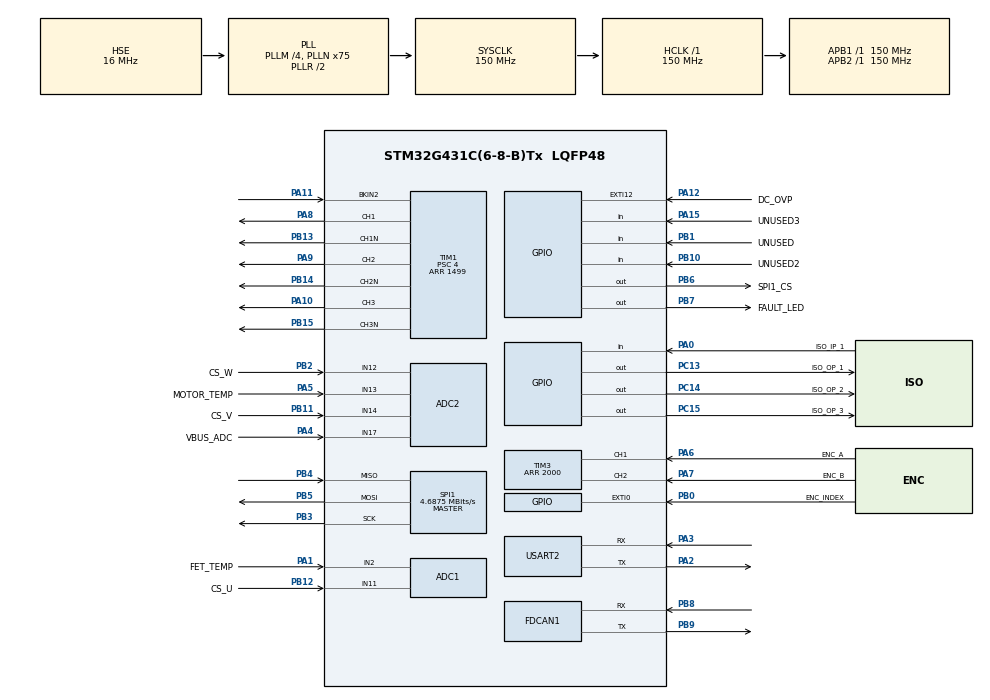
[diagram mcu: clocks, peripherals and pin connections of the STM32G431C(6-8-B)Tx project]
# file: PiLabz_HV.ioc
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ADC1.DMAContinuousRequests=ENABLE
ADC1.EnableRegularConversion=DISABLE
ADC1.GainCompensation=0
ADC1.OversamplingMode=ENABLE
ADC1.master=1
ADC2.DMAContinuousRequests=DISABLE
ADC2.EnableRegularConversion=DISABLE
ADC2.OversamplingMode=ENABLE
Dma.ADC1.0.Direction=DMA_PERIPH_TO_MEMORY
Dma.ADC1.0.EventEnable=DISABLE
Dma.ADC1.0.Instance=DMA1_Channel1
Dma.ADC1.0.MemDataAlignment=DMA_MDATAALIGN_HALFWORD
Dma.ADC1.0.MemInc=DMA_MINC_ENABLE
Dma.ADC1.0.Mode=DMA_CIRCULAR
Dma.ADC1.0.PeriphDataAlignment=DMA_PDATAALIGN_HALFWORD
Dma.ADC1.0.PeriphInc=DMA_PINC_DISABLE
Dma.ADC1.0.Polarity=HAL_DMAMUX_REQ_GEN_RISING
Dma.ADC1.0.Priority=DMA_PRIORITY_LOW
Dma.ADC1.0.RequestNumber=1
Dma.ADC1.0.SignalID=NONE
Dma.ADC1.0.SyncEnable=DISABLE
Dma.ADC1.0.SyncPolarity=HAL_DMAMUX_SYNC_NO_EVENT
Dma.ADC1.0.SyncRequestNumber=1
Dma.ADC1.0.SyncSignalID=NONE
Dma.Request0=ADC1
FDCAN1.CalculateBaudRateNominal=1874999
FDCAN1.CalculateTimeBitNominal=533
FDCAN1.CalculateTimeQuantumNominal=106.66666666666667
Mcu.Family=STM32G4
Mcu.Name=STM32G431C(6-8-B)Tx
Mcu.Package=LQFP48
NVIC.ADC1_2_IRQn=true\:0\:0\:false\:false\:true\:true\:true\:true
NVIC.DMA1_Channel1_IRQn=true\:0\:0\:false\:false\:true\:false\:true\:true
NVIC.PriorityGroup=NVIC_PRIORITYGROUP_4
NVIC.SPI1_IRQn=true\:0\:0\:false\:false\:true\:true\:true\:true
NVIC.TIM1_BRK_TIM15_IRQn=true\:0\:0\:true\:false\:true\:true\:true\:true
NVIC.TIM1_TRG_COM_TIM17_IRQn=true\:0\:0\:false\:false\:true\:true\:true\:true
NVIC.TIM1_UP_TIM16_IRQn=true\:1\:0\:true\:false\:true\:true\:true\:true
PA0.GPIO_Label=ISO_IP_1
PA0.Signal=GPIO_Input
PA1.GPIO_Label=FET_TEMP
PA1.Mode=IN2-Single-Ended
PA1.Signal=ADC1_IN2
PA10.Signal=S_TIM1_CH3
PA11.Mode=Activate-Break-Input-2
PA11.Signal=TIM1_BKIN2
PA12.GPIO_Label=DC_OVP
PA12.Signal=GPXTI12
PA13.Mode=Serial_Wire
PA13.Signal=SYS_JTMS-SWDIO
PA14.Mode=Serial_Wire
PA14.Signal=SYS_JTCK-SWCLK
PA15.GPIO_Label=UNUSED3
PA15.GPIO_PuPd=GPIO_PULLUP
PA15.Signal=GPIO_Input
PA2.Mode=Asynchronous
PA2.Signal=USART2_TX
PA3.Mode=Asynchronous
PA3.Signal=USART2_RX
PA4.GPIO_Label=VBUS_ADC
PA4.Mode=IN17-Single-Ended
PA4.Signal=ADC2_IN17
PA5.GPIO_Label=MOTOR_TEMP
PA5.Mode=IN13-Single-Ended
PA5.Signal=ADC2_IN13
PA6.GPIO_Label=ENC_A
PA6.Signal=S_TIM3_CH1
PA7.GPIO_Label=ENC_B
PA7.Signal=S_TIM3_CH2
PA8.Signal=S_TIM1_CH1
PA9.Signal=S_TIM1_CH2
PB0.GPIO_Label=ENC_INDEX
PB0.Signal=GPXTI0
PB1.GPIO_Label=UNUSED
PB1.GPIO_PuPd=GPIO_PULLUP
PB1.Signal=GPIO_Input
PB10.GPIO_Label=UNUSED2
PB10.GPIO_PuPd=GPIO_PULLUP
PB10.Signal=GPIO_Input
PB11.GPIO_Label=CS_V
PB11.Mode=IN14-Single-Ended
PB11.Signal=ADC2_IN14
PB12.GPIO_Label=CS_U
PB12.Mode=IN11-Single-Ended
PB12.Signal=ADC1_IN11
PB13.Mode=PWM Generation1 CH1 CH1N
PB13.Signal=TIM1_CH1N
PB14.Mode=PWM Generation2 CH2 CH2N
PB14.Signal=TIM1_CH2N
PB15.Mode=PWM Generation3 CH3 CH3N
PB15.Signal=TIM1_CH3N
PB2.GPIO_Label=CS_W
PB2.Mode=IN12-Single-Ended
PB2.Signal=ADC2_IN12
PB3.Mode=Full_Duplex_Master
PB3.Signal=SPI1_SCK
PB4.Mode=Full_Duplex_Master
PB4.Signal=SPI1_MISO
PB5.Mode=Full_Duplex_Master
PB5.Signal=SPI1_MOSI
PB6.GPIO_Label=SPI1_CS
PB6.GPIO_ModeDefaultOutputPP=GPIO_MODE_OUTPUT_PP
PB6.GPIO_PuPd=GPIO_NOPULL
PB6.PinState=GPIO_PIN_RESET
PB6.Signal=GPIO_Output
PB7.GPIO_Label=FAULT_LED
PB7.GPIO_ModeDefaultOutputPP=GPIO_MODE_OUTPUT_OD
PB7.GPIO_PuPd=GPIO_NOPULL
PB7.Signal=GPIO_Output
PB8-BOOT0.Mode=FDCAN_Activate
PB8-BOOT0.Signal=FDCAN1_RX
PB9.Mode=FDCAN_Activate
PB9.Signal=FDCAN1_TX
PC13.GPIO_Label=ISO_OP_1
PC13.GPIO_ModeDefaultOutputPP=GPIO_MODE_OUTPUT_OD
PC13.GPIO_PuPd=GPIO_NOPULL
PC13.Signal=GPIO_Output
PC14-OSC32_IN.GPIO_Label=ISO_OP_2
PC14-OSC32_IN.GPIO_ModeDefaultOutputPP=GPIO_MODE_OUTPUT_OD
PC14-OSC32_IN.GPIO_PuPd=GPIO_NOPULL
PC14-OSC32_IN.Signal=GPIO_Output
PC15-OSC32_OUT.GPIO_Label=ISO_OP_3
PC15-OSC32_OUT.GPIO_ModeDefaultOutputPP=GPIO_MODE_OUTPUT_OD
PC15-OSC32_OUT.GPIO_PuPd=GPIO_NOPULL
PC15-OSC32_OUT.PinState=GPIO_PIN_RESET
PC15-OSC32_OUT.Signal=GPIO_Output
PF0-OSC_IN.Mode=HSE-External-Oscillator
PF0-OSC_IN.Signal=RCC_OSC_IN
PF1-OSC_OUT.Mode=HSE-External-Oscillator
PF1-OSC_OUT.Signal=RCC_OSC_OUT
ProjectManager.HeapSize=0x200
ProjectManager.StackSize=0x400
ProjectManager.TargetToolchain=STM32CubeIDE
RCC.ADC12Freq_Value=150000000
RCC.AHBFreq_Value=150000000
RCC.APB1Freq_Value=150000000
RCC.APB1TimFreq_Value=150000000
RCC.APB2Freq_Value=150000000
RCC.APB2TimFreq_Value=150000000
RCC.CortexFreq_Value=150000000
RCC.EXTERNAL_CLOCK_VALUE=12288000
RCC.HCLKFreq_Value=150000000
RCC.HSE_VALUE=16000000
RCC.HSI48_VALUE=48000000
RCC.HSI_VALUE=16000000
RCC.LSE_VALUE=32768
RCC.PLLM=RCC_PLLM_DIV4
RCC.PLLN=75
RCC.PLLSourceVirtual=RCC_PLLSOURCE_HSE
RCC.SYSCLKFreq_VALUE=150000000
RCC.SYSCLKSource=RCC_SYSCLKSOURCE_PLLCLK
RCC.USBFreq_Value=150000000
RCC.VCOOutputFreq_Value=300000000
SH.S_TIM1_CH1.0=TIM1_CH1,PWM Generation1 CH1 CH1N
SH.S_TIM1_CH2.0=TIM1_CH2,PWM Generation2 CH2 CH2N
SH.S_TIM1_CH3.0=TIM1_CH3,PWM Generation3 CH3 CH3N
SH.S_TIM3_CH1.0=TIM3_CH1,Encoder_Interface
SH.S_TIM3_CH2.0=TIM3_CH2,Encoder_Interface
SPI1.BaudRatePrescaler=SPI_BAUDRATEPRESCALER_32
SPI1.CLKPhase=SPI_PHASE_2EDGE
SPI1.CalculateBaudRate=4.6875 MBits/s
SPI1.DataSize=SPI_DATASIZE_8BIT
SPI1.Direction=SPI_DIRECTION_2LINES
SPI1.Mode=SPI_MODE_MASTER
SPI1.VirtualType=VM_MASTER
TIM1.Channel-PWM\ Generation1\ CH1\ CH1N=TIM_CHANNEL_1
TIM1.Channel-PWM\ Generation2\ CH2\ CH2N=TIM_CHANNEL_2
TIM1.Channel-PWM\ Generation3\ CH3\ CH3N=TIM_CHANNEL_3
TIM1.CounterMode=TIM_COUNTERMODE_UP
TIM1.DeadTime=90
TIM1.DeadTimePreload=ENABLE
TIM1.OCMode_PWM-PWM\ Generation1\ CH1\ CH1N=TIM_OCMODE_PWM1
TIM1.OCNIdleState_1=TIM_OCNIDLESTATE_SET
TIM1.OCNIdleState_2=TIM_OCNIDLESTATE_SET
TIM1.OCNIdleState_3=TIM_OCNIDLESTATE_SET
TIM1.OCNPolarity_1=TIM_OCNPOLARITY_LOW
TIM1.OCNPolarity_2=TIM_OCNPOLARITY_LOW
TIM1.OCNPolarity_3=TIM_OCNPOLARITY_LOW
TIM1.PeriodNoDither=1499
TIM1.Prescaler=4
TIM3.PeriodNoDither=2000
USART2.VirtualMode-Asynchronous=VM_ASYNC
VP_SYS_VS_DBSignals.Mode=DisableDeadBatterySignals
VP_TIM1_VS_ClockSourceINT.Mode=Internal
board=custom

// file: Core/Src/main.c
/* USER CODE BEGIN Header */
/**
  ******************************************************************************
  * @file           : main.c
  * @brief          : Main program body
  ******************************************************************************
  * @attention
  *
  * Copyright (c) 2024 STMicroelectronics.
  * All rights reserved.
  *
  * This software is licensed under terms that can be found in the LICENSE file
  * in the root directory of this software component.
  * If no LICENSE file comes with this software, it is provided AS-IS.
  *
  ******************************************************************************
  */
/* USER CODE END Header */
#include "main.h"

/* USER CODE BEGIN Includes */
#include "EncoderFns.h"
/* USER CODE END Includes */

ADC_HandleTypeDef hadc1;
ADC_HandleTypeDef hadc2;
DMA_HandleTypeDef hdma_adc1;

FDCAN_HandleTypeDef hfdcan1;

SPI_HandleTypeDef hspi1;

TIM_HandleTypeDef htim1;
TIM_HandleTypeDef htim3;

UART_HandleTypeDef huart2;

void SystemClock_Config(void);
static void MX_GPIO_Init(void);
static void MX_DMA_Init(void);
static void MX_ADC1_Init(void);
static void MX_ADC2_Init(void);
static void MX_FDCAN1_Init(void);
static void MX_SPI1_Init(void);
static void MX_TIM1_Init(void);
static void MX_TIM3_Init(void);
static void MX_USART2_UART_Init(void);

/* USER CODE BEGIN 0 */
float angleMech=0;
/* USER CODE END 0 */

int main(void)
{

  /* MCU Configuration--------------------------------------------------------*/

  /* Reset of all peripherals, Initializes the Flash interface and the Systick. */
  HAL_Init();

  /* Configure the system clock */
  SystemClock_Config();

  /* Initialize all configured peripherals */
  MX_GPIO_Init();
  MX_DMA_Init();
  MX_ADC1_Init();
  MX_ADC2_Init();
  MX_FDCAN1_Init();
  MX_SPI1_Init();
  MX_TIM1_Init();
  MX_TIM3_Init();
  MX_USART2_UART_Init();

  /* Infinite loop */
  /* USER CODE BEGIN WHILE */
  while (1)
  {

	angleMech = getEncoderAngleFromSPI(1);
	HAL_GPIO_TogglePin(GPIOB,FAULT_LED_Pin);
	HAL_Delay(100);

    /* USER CODE END WHILE */

  }
}

void SystemClock_Config(void)
{
  RCC_OscInitTypeDef RCC_OscInitStruct = {0};
  RCC_ClkInitTypeDef RCC_ClkInitStruct = {0};

  /** Configure the main internal regulator output voltage
  */
  HAL_PWREx_ControlVoltageScaling(PWR_REGULATOR_VOLTAGE_SCALE1);

  /** Initializes the RCC Oscillators according to the specified parameters
  * in the RCC_OscInitTypeDef structure.
  */
  RCC_OscInitStruct.OscillatorType = RCC_OSCILLATORTYPE_HSE;
  RCC_OscInitStruct.HSEState = RCC_HSE_ON;
  RCC_OscInitStruct.PLL.PLLState = RCC_PLL_ON;
  RCC_OscInitStruct.PLL.PLLSource = RCC_PLLSOURCE_HSE;
  RCC_OscInitStruct.PLL.PLLM = RCC_PLLM_DIV4;
  RCC_OscInitStruct.PLL.PLLN = 75;
  RCC_OscInitStruct.PLL.PLLP = RCC_PLLP_DIV2;
  RCC_OscInitStruct.PLL.PLLQ = RCC_PLLQ_DIV2;
  RCC_OscInitStruct.PLL.PLLR = RCC_PLLR_DIV2;
  if (HAL_RCC_OscConfig(&RCC_OscInitStruct) != HAL_OK)
  {
    Error_Handler();
  }

  /** Initializes the CPU, AHB and APB buses clocks
  */
  RCC_ClkInitStruct.ClockType = RCC_CLOCKTYPE_HCLK|RCC_CLOCKTYPE_SYSCLK
                              |RCC_CLOCKTYPE_PCLK1|RCC_CLOCKTYPE_PCLK2;
  RCC_ClkInitStruct.SYSCLKSource = RCC_SYSCLKSOURCE_PLLCLK;
  RCC_ClkInitStruct.AHBCLKDivider = RCC_SYSCLK_DIV1;
  RCC_ClkInitStruct.APB1CLKDivider = RCC_HCLK_DIV1;
  RCC_ClkInitStruct.APB2CLKDivider = RCC_HCLK_DIV1;

  if (HAL_RCC_ClockConfig(&RCC_ClkInitStruct, FLASH_LATENCY_4) != HAL_OK)
  {
    Error_Handler();
  }
}

static void MX_ADC1_Init(void)
{

  ADC_MultiModeTypeDef multimode = {0};

  /** Common config
  */
  hadc1.Instance = ADC1;
  hadc1.Init.ClockPrescaler = ADC_CLOCK_SYNC_PCLK_DIV4;
  hadc1.Init.Resolution = ADC_RESOLUTION_12B;
  hadc1.Init.DataAlign = ADC_DATAALIGN_RIGHT;
  hadc1.Init.GainCompensation = 0;
  hadc1.Init.ScanConvMode = ADC_SCAN_DISABLE;
  hadc1.Init.EOCSelection = ADC_EOC_SINGLE_CONV;
  hadc1.Init.LowPowerAutoWait = DISABLE;
  hadc1.Init.ContinuousConvMode = DISABLE;
  hadc1.Init.NbrOfConversion = 1;
  hadc1.Init.DiscontinuousConvMode = DISABLE;
  hadc1.Init.DMAContinuousRequests = ENABLE;
  hadc1.Init.Overrun = ADC_OVR_DATA_PRESERVED;
  hadc1.Init.OversamplingMode = ENABLE;
  if (HAL_ADC_Init(&hadc1) != HAL_OK)
  {
    Error_Handler();
  }

  /** Configure the ADC multi-mode
  */
  multimode.Mode = ADC_MODE_INDEPENDENT;
  if (HAL_ADCEx_MultiModeConfigChannel(&hadc1, &multimode) != HAL_OK)
  {
    Error_Handler();
  }

}

static void MX_ADC2_Init(void)
{

  /** Common config
  */
  hadc2.Instance = ADC2;
  hadc2.Init.ClockPrescaler = ADC_CLOCK_SYNC_PCLK_DIV4;
  hadc2.Init.Resolution = ADC_RESOLUTION_12B;
  hadc2.Init.DataAlign = ADC_DATAALIGN_RIGHT;
  hadc2.Init.GainCompensation = 0;
  hadc2.Init.ScanConvMode = ADC_SCAN_DISABLE;
  hadc2.Init.EOCSelection = ADC_EOC_SINGLE_CONV;
  hadc2.Init.LowPowerAutoWait = DISABLE;
  hadc2.Init.ContinuousConvMode = DISABLE;
  hadc2.Init.NbrOfConversion = 1;
  hadc2.Init.DiscontinuousConvMode = DISABLE;
  hadc2.Init.DMAContinuousRequests = DISABLE;
  hadc2.Init.Overrun = ADC_OVR_DATA_PRESERVED;
  hadc2.Init.OversamplingMode = ENABLE;
  if (HAL_ADC_Init(&hadc2) != HAL_OK)
  {
    Error_Handler();
  }

}

static void MX_FDCAN1_Init(void)
{

  hfdcan1.Instance = FDCAN1;
  hfdcan1.Init.ClockDivider = FDCAN_CLOCK_DIV1;
  hfdcan1.Init.FrameFormat = FDCAN_FRAME_CLASSIC;
  hfdcan1.Init.Mode = FDCAN_MODE_NORMAL;
  hfdcan1.Init.AutoRetransmission = DISABLE;
  hfdcan1.Init.TransmitPause = DISABLE;
  hfdcan1.Init.ProtocolException = DISABLE;
  hfdcan1.Init.NominalPrescaler = 16;
  hfdcan1.Init.NominalSyncJumpWidth = 1;
  hfdcan1.Init.NominalTimeSeg1 = 2;
  hfdcan1.Init.NominalTimeSeg2 = 2;
  hfdcan1.Init.DataPrescaler = 1;
  hfdcan1.Init.DataSyncJumpWidth = 1;
  hfdcan1.Init.DataTimeSeg1 = 1;
  hfdcan1.Init.DataTimeSeg2 = 1;
  hfdcan1.Init.StdFiltersNbr = 0;
  hfdcan1.Init.ExtFiltersNbr = 0;
  hfdcan1.Init.TxFifoQueueMode = FDCAN_TX_FIFO_OPERATION;
  if (HAL_FDCAN_Init(&hfdcan1) != HAL_OK)
  {
    Error_Handler();
  }

}

static void MX_SPI1_Init(void)
{

  /* SPI1 parameter configuration*/
  hspi1.Instance = SPI1;
  hspi1.Init.Mode = SPI_MODE_MASTER;
  hspi1.Init.Direction = SPI_DIRECTION_2LINES;
  hspi1.Init.DataSize = SPI_DATASIZE_8BIT;
  hspi1.Init.CLKPolarity = SPI_POLARITY_LOW;
  hspi1.Init.CLKPhase = SPI_PHASE_2EDGE;
  hspi1.Init.NSS = SPI_NSS_SOFT;
  hspi1.Init.BaudRatePrescaler = SPI_BAUDRATEPRESCALER_32;
  hspi1.Init.FirstBit = SPI_FIRSTBIT_MSB;
  hspi1.Init.TIMode = SPI_TIMODE_DISABLE;
  hspi1.Init.CRCCalculation = SPI_CRCCALCULATION_DISABLE;
  hspi1.Init.CRCPolynomial = 7;
  hspi1.Init.CRCLength = SPI_CRC_LENGTH_DATASIZE;
  hspi1.Init.NSSPMode = SPI_NSS_PULSE_DISABLE;
  if (HAL_SPI_Init(&hspi1) != HAL_OK)
  {
    Error_Handler();
  }

}

static void MX_TIM1_Init(void)
{

  TIM_ClockConfigTypeDef sClockSourceConfig = {0};
  TIM_MasterConfigTypeDef sMasterConfig = {0};
  TIMEx_BreakInputConfigTypeDef sBreakInputConfig = {0};
  TIM_OC_InitTypeDef sConfigOC = {0};
  TIM_BreakDeadTimeConfigTypeDef sBreakDeadTimeConfig = {0};

  htim1.Instance = TIM1;
  htim1.Init.Prescaler = 4;
  htim1.Init.CounterMode = TIM_COUNTERMODE_UP;
  htim1.Init.Period = 1499;
  htim1.Init.ClockDivision = TIM_CLOCKDIVISION_DIV1;
  htim1.Init.RepetitionCounter = 0;
  htim1.Init.AutoReloadPreload = TIM_AUTORELOAD_PRELOAD_DISABLE;
  if (HAL_TIM_Base_Init(&htim1) != HAL_OK)
  {
    Error_Handler();
  }
  sClockSourceConfig.ClockSource = TIM_CLOCKSOURCE_INTERNAL;
  if (HAL_TIM_ConfigClockSource(&htim1, &sClockSourceConfig) != HAL_OK)
  {
    Error_Handler();
  }
  if (HAL_TIM_PWM_Init(&htim1) != HAL_OK)
  {
    Error_Handler();
  }
  sMasterConfig.MasterOutputTrigger = TIM_TRGO_RESET;
  sMasterConfig.MasterOutputTrigger2 = TIM_TRGO2_RESET;
  sMasterConfig.MasterSlaveMode = TIM_MASTERSLAVEMODE_DISABLE;
  if (HAL_TIMEx_MasterConfigSynchronization(&htim1, &sMasterConfig) != HAL_OK)
  {
    Error_Handler();
  }
  sBreakInputConfig.Source = TIM_BREAKINPUTSOURCE_BKIN;
  sBreakInputConfig.Enable = TIM_BREAKINPUTSOURCE_ENABLE;
  sBreakInputConfig.Polarity = TIM_BREAKINPUTSOURCE_POLARITY_HIGH;
  if (HAL_TIMEx_ConfigBreakInput(&htim1, TIM_BREAKINPUT_BRK2, &sBreakInputConfig) != HAL_OK)
  {
    Error_Handler();
  }
  sConfigOC.OCMode = TIM_OCMODE_PWM1;
  sConfigOC.Pulse = 0;
  sConfigOC.OCPolarity = TIM_OCPOLARITY_HIGH;
  sConfigOC.OCNPolarity = TIM_OCNPOLARITY_LOW;
  sConfigOC.OCFastMode = TIM_OCFAST_DISABLE;
  sConfigOC.OCIdleState = TIM_OCIDLESTATE_RESET;
  sConfigOC.OCNIdleState = TIM_OCNIDLESTATE_SET;
  if (HAL_TIM_PWM_ConfigChannel(&htim1, &sConfigOC, TIM_CHANNEL_1) != HAL_OK)
  {
    Error_Handler();
  }
  if (HAL_TIM_PWM_ConfigChannel(&htim1, &sConfigOC, TIM_CHANNEL_2) != HAL_OK)
  {
    Error_Handler();
  }
  if (HAL_TIM_PWM_ConfigChannel(&htim1, &sConfigOC, TIM_CHANNEL_3) != HAL_OK)
  {
    Error_Handler();
  }
  HAL_TIMEx_EnableDeadTimePreload(&htim1);
  sBreakDeadTimeConfig.OffStateRunMode = TIM_OSSR_ENABLE;
  sBreakDeadTimeConfig.OffStateIDLEMode = TIM_OSSI_ENABLE;
  sBreakDeadTimeConfig.LockLevel = TIM_LOCKLEVEL_OFF;
  sBreakDeadTimeConfig.DeadTime = 90;
  sBreakDeadTimeConfig.BreakState = TIM_BREAK_DISABLE;
  sBreakDeadTimeConfig.BreakPolarity = TIM_BREAKPOLARITY_HIGH;
  sBreakDeadTimeConfig.BreakFilter = 0;
  sBreakDeadTimeConfig.BreakAFMode = TIM_BREAK_AFMODE_INPUT;
  sBreakDeadTimeConfig.Break2State = TIM_BREAK2_ENABLE;
  sBreakDeadTimeConfig.Break2Polarity = TIM_BREAK2POLARITY_HIGH;
  sBreakDeadTimeConfig.Break2Filter = 0;
  sBreakDeadTimeConfig.Break2AFMode = TIM_BREAK_AFMODE_INPUT;
  sBreakDeadTimeConfig.AutomaticOutput = TIM_AUTOMATICOUTPUT_DISABLE;
  if (HAL_TIMEx_ConfigBreakDeadTime(&htim1, &sBreakDeadTimeConfig) != HAL_OK)
  {
    Error_Handler();
  }
  HAL_TIM_MspPostInit(&htim1);

}

static void MX_TIM3_Init(void)
{

  TIM_Encoder_InitTypeDef sConfig = {0};
  TIM_MasterConfigTypeDef sMasterConfig = {0};

  htim3.Instance = TIM3;
  htim3.Init.Prescaler = 0;
  htim3.Init.CounterMode = TIM_COUNTERMODE_UP;
  htim3.Init.Period = 2000;
  htim3.Init.ClockDivision = TIM_CLOCKDIVISION_DIV1;
  htim3.Init.AutoReloadPreload = TIM_AUTORELOAD_PRELOAD_DISABLE;
  sConfig.EncoderMode = TIM_ENCODERMODE_TI1;
  sConfig.IC1Polarity = TIM_ICPOLARITY_RISING;
  sConfig.IC1Selection = TIM_ICSELECTION_DIRECTTI;
  sConfig.IC1Prescaler = TIM_ICPSC_DIV1;
  sConfig.IC1Filter = 0;
  sConfig.IC2Polarity = TIM_ICPOLARITY_RISING;
  sConfig.IC2Selection = TIM_ICSELECTION_DIRECTTI;
  sConfig.IC2Prescaler = TIM_ICPSC_DIV1;
  sConfig.IC2Filter = 0;
  if (HAL_TIM_Encoder_Init(&htim3, &sConfig) != HAL_OK)
  {
    Error_Handler();
  }
  sMasterConfig.MasterOutputTrigger = TIM_TRGO_RESET;
  sMasterConfig.MasterSlaveMode = TIM_MASTERSLAVEMODE_DISABLE;
  if (HAL_TIMEx_MasterConfigSynchronization(&htim3, &sMasterConfig) != HAL_OK)
  {
    Error_Handler();
  }

}

static void MX_USART2_UART_Init(void)
{

  huart2.Instance = USART2;
  huart2.Init.BaudRate = 115200;
  huart2.Init.WordLength = UART_WORDLENGTH_8B;
  huart2.Init.StopBits = UART_STOPBITS_1;
  huart2.Init.Parity = UART_PARITY_NONE;
  huart2.Init.Mode = UART_MODE_TX_RX;
  huart2.Init.HwFlowCtl = UART_HWCONTROL_NONE;
  huart2.Init.OverSampling = UART_OVERSAMPLING_16;
  huart2.Init.OneBitSampling = UART_ONE_BIT_SAMPLE_DISABLE;
  huart2.Init.ClockPrescaler = UART_PRESCALER_DIV1;
  huart2.AdvancedInit.AdvFeatureInit = UART_ADVFEATURE_NO_INIT;
  if (HAL_UART_Init(&huart2) != HAL_OK)
  {
    Error_Handler();
  }
  if (HAL_UARTEx_SetTxFifoThreshold(&huart2, UART_TXFIFO_THRESHOLD_1_8) != HAL_OK)
  {
    Error_Handler();
  }
  if (HAL_UARTEx_SetRxFifoThreshold(&huart2, UART_RXFIFO_THRESHOLD_1_8) != HAL_OK)
  {
    Error_Handler();
  }
  if (HAL_UARTEx_DisableFifoMode(&huart2) != HAL_OK)
  {
    Error_Handler();
  }

}

static void MX_DMA_Init(void)
{

  /* DMA controller clock enable */
  __HAL_RCC_DMAMUX1_CLK_ENABLE();
  __HAL_RCC_DMA1_CLK_ENABLE();

  /* DMA interrupt init */
  /* DMA1_Channel1_IRQn interrupt configuration */
  HAL_NVIC_SetPriority(DMA1_Channel1_IRQn, 0, 0);
  HAL_NVIC_EnableIRQ(DMA1_Channel1_IRQn);

}

static void MX_GPIO_Init(void)
{
  GPIO_InitTypeDef GPIO_InitStruct = {0};

  /* GPIO Ports Clock Enable */
  __HAL_RCC_GPIOC_CLK_ENABLE();
  __HAL_RCC_GPIOF_CLK_ENABLE();
  __HAL_RCC_GPIOA_CLK_ENABLE();
  __HAL_RCC_GPIOB_CLK_ENABLE();

  /*Configure GPIO pin Output Level */
  HAL_GPIO_WritePin(GPIOC, ISO_OP_1_Pin|ISO_OP_2_Pin|ISO_OP_3_Pin, GPIO_PIN_RESET);

  /*Configure GPIO pin Output Level */
  HAL_GPIO_WritePin(GPIOB, SPI1_CS_Pin|FAULT_LED_Pin, GPIO_PIN_RESET);

  /*Configure GPIO pins : ISO_OP_1_Pin ISO_OP_2_Pin ISO_OP_3_Pin */
  GPIO_InitStruct.Pin = ISO_OP_1_Pin|ISO_OP_2_Pin|ISO_OP_3_Pin;
  GPIO_InitStruct.Mode = GPIO_MODE_OUTPUT_OD;
  GPIO_InitStruct.Pull = GPIO_NOPULL;
  GPIO_InitStruct.Speed = GPIO_SPEED_FREQ_LOW;
  HAL_GPIO_Init(GPIOC, &GPIO_InitStruct);

  /*Configure GPIO pin : ISO_IP_1_Pin */
  GPIO_InitStruct.Pin = ISO_IP_1_Pin;
  GPIO_InitStruct.Mode = GPIO_MODE_INPUT;
  GPIO_InitStruct.Pull = GPIO_NOPULL;
  HAL_GPIO_Init(ISO_IP_1_GPIO_Port, &GPIO_InitStruct);

  /*Configure GPIO pin : ENC_INDEX_Pin */
  GPIO_InitStruct.Pin = ENC_INDEX_Pin;
  GPIO_InitStruct.Mode = GPIO_MODE_IT_RISING;
  GPIO_InitStruct.Pull = GPIO_NOPULL;
  HAL_GPIO_Init(ENC_INDEX_GPIO_Port, &GPIO_InitStruct);

  /*Configure GPIO pins : UNUSED_Pin UNUSED2_Pin */
  GPIO_InitStruct.Pin = UNUSED_Pin|UNUSED2_Pin;
  GPIO_InitStruct.Mode = GPIO_MODE_INPUT;
  GPIO_InitStruct.Pull = GPIO_PULLUP;
  HAL_GPIO_Init(GPIOB, &GPIO_InitStruct);

  /*Configure GPIO pin : DC_OVP_Pin */
  GPIO_InitStruct.Pin = DC_OVP_Pin;
  GPIO_InitStruct.Mode = GPIO_MODE_IT_RISING;
  GPIO_InitStruct.Pull = GPIO_NOPULL;
  HAL_GPIO_Init(DC_OVP_GPIO_Port, &GPIO_InitStruct);

  /*Configure GPIO pin : UNUSED3_Pin */
  GPIO_InitStruct.Pin = UNUSED3_Pin;
  GPIO_InitStruct.Mode = GPIO_MODE_INPUT;
  GPIO_InitStruct.Pull = GPIO_PULLUP;
  HAL_GPIO_Init(UNUSED3_GPIO_Port, &GPIO_InitStruct);

  /*Configure GPIO pin : SPI1_CS_Pin */
  GPIO_InitStruct.Pin = SPI1_CS_Pin;
  GPIO_InitStruct.Mode = GPIO_MODE_OUTPUT_PP;
  GPIO_InitStruct.Pull = GPIO_NOPULL;
  GPIO_InitStruct.Speed = GPIO_SPEED_FREQ_LOW;
  HAL_GPIO_Init(SPI1_CS_GPIO_Port, &GPIO_InitStruct);

  /*Configure GPIO pin : FAULT_LED_Pin */
  GPIO_InitStruct.Pin = FAULT_LED_Pin;
  GPIO_InitStruct.Mode = GPIO_MODE_OUTPUT_OD;
  GPIO_InitStruct.Pull = GPIO_NOPULL;
  GPIO_InitStruct.Speed = GPIO_SPEED_FREQ_LOW;
  HAL_GPIO_Init(FAULT_LED_GPIO_Port, &GPIO_InitStruct);

}

void Error_Handler(void)
{
  __disable_irq();
  while (1)
  {
  }
}
